# DA1470x register map
Vendor: Dialog; Series: DA1470x; File version: 1.2
CPU: CM33 r0p2, little endian, MPU, FPU, DSP, VTOR, 4 interrupt priority bits
Registers are 32-bit, read-write, reset 0x0 unless marked. A register's access mark holds for its fields unless they carry their own. Offsets are from the block's base; [hi:lo] are bit positions; 'fields as' and 'values as' point back to an identical list.

## LCDC — LCDC registers
Base 0x30030000
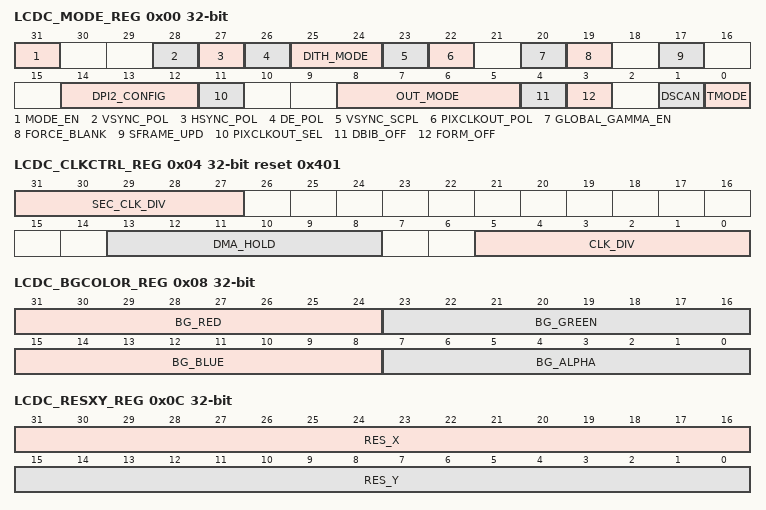
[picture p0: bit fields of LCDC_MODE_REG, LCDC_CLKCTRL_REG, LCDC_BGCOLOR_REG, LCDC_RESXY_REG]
0x00 LCDC_MODE_REG (reset mask 0x7FFFFFFF) — Display Mode
  [31] MODE_EN — Mode register. 0 : disable 1 : enable
  [28] VSYNC_POL — VSYNC polarity. 0: positive 1: negative
  [27] HSYNC_POL — HSYNC polarity. 0: positive 1: negative
  [26] DE_POL — DE polarity. 0: positive 1: negative
  [25:24] DITH_MODE — 0x00: Dithering is disabled 0x01: Dithering 18-bits mode 0x02: Dithering 16-bits mode 0x03: Dithering 15-bits mode
  [23] VSYNC_SCPL — Set VSYNC for a single cycle per line. 0: disable 1: enable
  [22] PIXCLKOUT_POL — Pixel clock out polarity. 0: positive 1: negative
  [20] GLOBAL_GAMMA_EN — When set to 1, global gamma correction is enabled
  [19] FORCE_BLANK — Forces output to blank. 0: disable 1: enable
  [17] SFRAME_UPD — Single frame update. 0: disable 1: enable
  [14:12] DPI2_CONFIG — Defines MIPI DPI-2 Configuration 0x00: RGB888 24-bits 0x01: RGB666 18-bits Configuration 1 0x02: RGB666 18-bits Configuration 2 0x03: RGB565 16-bits Configuration 1 0x04: RGB565 16-bits Configuration 2 0x05: RGB565 16-bits Configuration 3 0x06: Reserved 0x07: Reserved
  [11] PIXCLKOUT_SEL — Selects the pixel out clock for the display. 0: based on the pixel pipeline clock 1: based on the format pipeline clock See also the LCDC_CLKCTRL_REG.
  [8:5] OUT_MODE — Selection of the output mode 0000: Parallel RGB 1000: JDI MIP All the other values are reserved.
  [4] DBIB_OFF — When set to 0, DBI Type-B interface is enabled
  [3] FORM_OFF — Formating off 0: disabled 1: enabled
  [1] DSCAN — Double horizontal scan 0: disabled 1: enabled
  [0] TMODE — Test mode 0: disabled 1: enabled
0x04 LCDC_CLKCTRL_REG reset 0x401 (reset mask 0x7FFFFFFF) — Clock Divider
  [31:27] SEC_CLK_DIV — Secondary clock divider that generates the format pipeline clock. Source clock of this divider is the main clock of LCD controller. The period of the generated clock is defined as : (LCDC_SEC_CLK_DIV + 1) x period_of_main_clock.
  [13:8] DMA_HOLD — Hold time before DMA activated.
  [5:0] CLK_DIV — Clock divider that generates the pixel pipeline clock. Source clock of this divider is the format pipeline clock (see also LCDC_SEC_CLK_DIV). The period of the generated clock is defines as : LCDC_CLK_DIV x period_of_format_clk. A zero value gives division by one.
0x08 LCDC_BGCOLOR_REG (reset mask 0x7FFFFFFF) — Background Color
  [31:24] BG_RED — Red color used as background.
  [23:16] BG_GREEN — Green color used as background.
  [15:8] BG_BLUE — Blue color used as background.
  [7:0] BG_ALPHA — Alpha color used as background.
0x0C LCDC_RESXY_REG (reset mask 0x7FFFFFFF) — Resolution X,Y
  [31:16] RES_X — Resolution X in pixels.
  [15:0] RES_Y — Resolution Y in pixels.
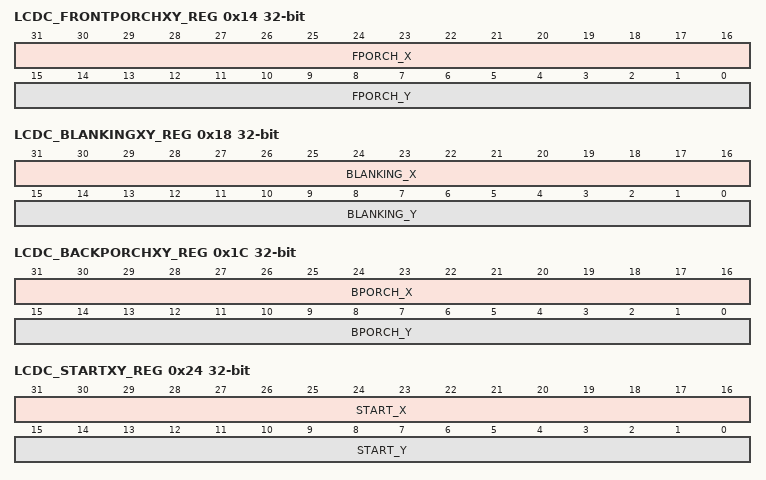
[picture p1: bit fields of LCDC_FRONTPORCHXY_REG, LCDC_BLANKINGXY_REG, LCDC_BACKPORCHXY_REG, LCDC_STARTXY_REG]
0x14 LCDC_FRONTPORCHXY_REG (reset mask 0x7FFFFFFF) — Front Porch X and Y
  [31:16] FPORCH_X — Front porch X (lines)
  [15:0] FPORCH_Y — Front porch Y (pixel clocks)
0x18 LCDC_BLANKINGXY_REG (reset mask 0x7FFFFFFF) — Blanking X and Y
  [31:16] BLANKING_X — Blanking period X (VSYNC lines)
  [15:0] BLANKING_Y — Blanking period Y (HSYNC pulse length)
0x1C LCDC_BACKPORCHXY_REG (reset mask 0x7FFFFFFF) — Back Porch X and Y
  [31:16] BPORCH_X — Back porch X (lines)
  [15:0] BPORCH_Y — Back porch Y (pixel clocks)
0x24 LCDC_STARTXY_REG (reset mask 0x7FFFFFFF) — Specifies the start position of the very first frame
  [31:16] START_X — Specify framess X dimension
  [15:0] START_Y — Specify framess Y dimension
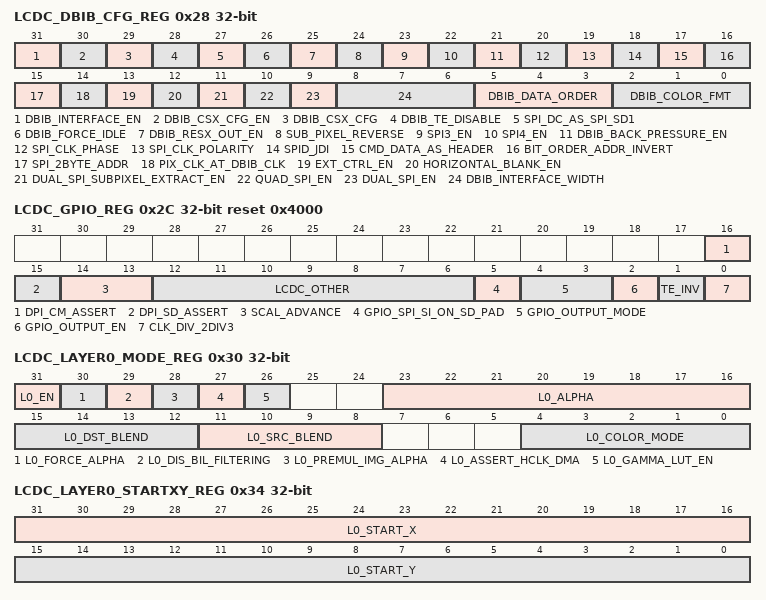
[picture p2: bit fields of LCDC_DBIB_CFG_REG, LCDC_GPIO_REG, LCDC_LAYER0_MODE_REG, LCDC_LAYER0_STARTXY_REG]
0x28 LCDC_DBIB_CFG_REG (reset mask 0x7FFFFFFF) — MIPI Config Register
  [31] DBIB_INTERFACE_EN — When set to 1, the DBI Type-B interface is activated
  [30] DBIB_CSX_CFG_EN — When set to 1, the value of the CSX signal of the DBI Type-B interface can be configured from the DBIB_CFG[29] register bit
  [29] DBIB_CSX_CFG — Sets the value of DBIB_CSX signal: CSX is set to one if DBIB_CFG[29] has the value of one CSX is set to zero if DBIB_CFG[29] has the value of zero
  [28] DBIB_TE_DISABLE — When set to 1, the DBIB_TE signal is disabled
  [27] SPI_DC_AS_SPI_SD1 — When set to 1, enables the usage of SPI_DC wire as SPI_SD1
  [26] DBIB_FORCE_IDLE — When set to 1, force DBI Type-B interface to idle state. Swap on the fly data for the interface
  [25] DBIB_RESX_OUT_EN — Drives DBIB_RESX output signal of DBI Type-B interface
  [24] SUB_PIXEL_REVERSE — Reverse sub pixel order
  [23] SPI3_EN — When set to 1, SPI 3-wire interface is enabled
  [22] SPI4_EN — When set to 1, SPI 4-wire interface is enabled
  [21] DBIB_BACK_PRESSURE_EN — When set to 1, Enables back-pressure for DBI Type-B interface
  [20] SPI_CLK_PHASE — Sets SPI Clock Phase
  [19] SPI_CLK_POLARITY — Sets SPI Clock Polarity
  [18] SPID_JDI
  [17] CMD_DATA_AS_HEADER — When set to 1, command data are used as header of each line
  [16] BIT_ORDER_ADDR_INVERT — When set to 1, inverts the bit-order of the horizontal line address (used along with DBIB_CFG[17] register bit)
  [15] SPI_2BYTE_ADDR — When set to 1, two-byte address is sent with each horizontal line (SPI)
  [14] PIX_CLK_AT_DBIB_CLK — When set to 1, expose pixel generation clock on the DBIB_CLK
  [13] EXT_CTRL_EN — When set to 1, enables the external control
  [12] HORIZONTAL_BLANK_EN — When set to 1, enables the horizontal blanking
  [11] DUAL_SPI_SUBPIXEL_EXTRACT_EN — When set to 1, Enables DualSPI sub-pixel transaction
  [10] QUAD_SPI_EN — When set to 1, Enables QuadSPI
  [9] DUAL_SPI_EN — When set to 1, Enables DualSPI
  [8:6] DBIB_INTERFACE_WIDTH — Set DBI Type-B interface width (8, 9 or 16 bits) and the serial interface: 0x0: 8-bit interface 0x1: 9-bit interface 0x2: 16-bit interface 0x3: SPI 0x4: Dual SPI 0x5: Quad SPI
  [5:3] DBIB_DATA_ORDER — Set the data order of the 8-bit data word: 0x0: option 0 0x1: option 1 0x2: option 2 0x3: option 3 0x4: option 4 0x5: Reserved 0x6: Reserved 0x7: Reserved
  [2:0] DBIB_COLOR_FMT — Defines the output format and depends of the type of the output interface. For the SPI3/SPI4 are supported the following formats: 0x0 : Reserved 0x1 : RGB111 0x2 : RGB332 0x3 : RGB444 0x4 : Reserved 0x5 : RGB565 0x6 : RGB666 0x7 : RGB888
0x2C LCDC_GPIO_REG reset 0x4000 — General Purpose IO (8-bits)
  [16] DPI_CM_ASSERT wo — Assert DPI-2 Color Mode signal
  [15] DPI_SD_ASSERT wo — Assert DPI-2 Shutdown signal
  [14:13] SCAL_ADVANCE — scalar advance
  [12:6] LCDC_OTHER
  [5] GPIO_SPI_SI_ON_SD_PAD — Enable to have the SPI SI on the SPI SD pad
  [4:3] GPIO_OUTPUT_MODE — Select the mode that should be mapped on the GPIO pins 0x0 = JDI 0x1 = DPI 0x2 = DBI 0x3 = SPI
  [2] GPIO_OUTPUT_EN — Enable the GPIO pins for LCDC control. The GPIO_OUTPUT_MODE is used to define what LCDC pins will be mapped towards the GPIO pins.
  [1] TE_INV — Applies an inversion on the TE (tearing effect) signal. 0 : the inversion is not applied on the TE signal 1 : the inversion is applied on TE signal
  [0] CLK_DIV_2DIV3 — Divide clock by 2/3 clock-gating. This is required when the DSI-DPHY is used with 2 lanes active.
0x30 LCDC_LAYER0_MODE_REG (reset mask 0x7FFFFFFF) — Layer0 Mode
  [31] L0_EN — Enable layer. 0 : disable 1 : enable
  [30] L0_FORCE_ALPHA — When set to 1, force alpha with global alpha
  [29] L0_DIS_BIL_FILTERING — When set to 0, bilinear filtering is enabled. Scaler should be enabled
  [28] L0_PREMUL_IMG_ALPHA — When set to 1, premultiply image alpha is enabled
  [27] L0_ASSERT_HCLK_DMA — When set to 1, HLOCK signal on AHB DMAs is asserted
  [26] L0_GAMMA_LUT_EN — When set to 1, Gamma Look Up Table is enabled
  [23:16] L0_ALPHA — Alpha layer global value (0x00-0xFF range)
  [15:12] L0_DST_BLEND — Destinary Blending Function 0000: BLEND ZERO 0001: BLEND ONE 0010: BLEND ALPHA SRC 0011: BLEND ALPHA GBL 0100: BLEND ALPHA SRCGBL 0101: BLEND INV SRC 0110: BLEND INV GBL 0111: BLEND INV SRCGBL 1010: BLEND ALPHA DST 1101: BLEND INV DST
  [11:8] L0_SRC_BLEND — Source Blending Function 0000: BLEND ZERO 0001: BLEND ONE 0010: BLEND ALPHA SRC 0011: BLEND ALPHA GBL 0100: BLEND ALPHA SRCGBL 0101: BLEND INV SRC 0110: BLEND INV GBL 0111: BLEND INV SRCGBL 1010: BLEND ALPHA DST 1101: BLEND INV DST
  [4:0] L0_COLOR_MODE — Color Mode: 00001: 16-bit RGBX5551 color format, 00010: 32-bit RGBX8888 color format, 00100: 8-bit RGB332 color format, 00101: 16-bit RGB565 color format, 00110: 32-bit XRGB8888, 00111: L8 Grayscale/Palette format, 01000: L1 Grayscale/Palette format, 01001: L4 Grayscale/Palette format, 01101: ABGR8888, 01110: BGRA8888
0x34 LCDC_LAYER0_STARTXY_REG (reset mask 0x7FFFFFFF) — Layer0 Start XY
  [31:16] L0_START_X — Start X (offset pixels)
  [15:0] L0_START_Y — Start Y (offset pixels)
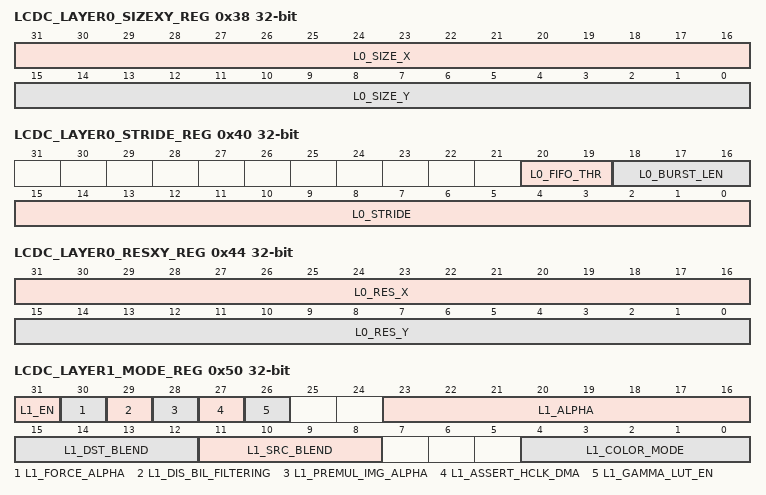
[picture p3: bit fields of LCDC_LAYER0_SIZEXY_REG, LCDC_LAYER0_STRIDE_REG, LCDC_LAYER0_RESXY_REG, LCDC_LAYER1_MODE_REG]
0x38 LCDC_LAYER0_SIZEXY_REG (reset mask 0x7FFFFFFF) — Layer0 Size XY
  [31:16] L0_SIZE_X — Size X (Size of layer in pixels)
  [15:0] L0_SIZE_Y — Size Y (Size of layer in pixels)
0x3C LCDC_LAYER0_BASEADDR_REG (reset mask 0x7FFFFFFF) — Layer0 Base Addr
  [31:0] L0_BASE_ADDR — Base Address of the frame buffer
0x40 LCDC_LAYER0_STRIDE_REG — Layer0 Stride
  [20:19] L0_FIFO_THR — Layer dma fifo threshold burst start 00: half fifo (default) 01: 2 burst size 10: 4 burst size 11: 8 burst size
  [18:16] L0_BURST_LEN — Layer burst length 000: 16-beats (default) 001: 2-beats 010: 4-beats 011: 8-beats 100: 16-beats
  [15:0] L0_STRIDE — Layer Stride (distance from line to line in bytes)
0x44 LCDC_LAYER0_RESXY_REG (reset mask 0x7FFFFFFF) — Layer0 Res XY
  [31:16] L0_RES_X — Resolution X (Resolution of layer in pixels)
  [15:0] L0_RES_Y — Resolution Y (Resolution of layer in pixels)
0x50 LCDC_LAYER1_MODE_REG (reset mask 0x7FFFFFFF) — Layer1 Mode
  [31] L1_EN — Enable layer. 0 : disable 1 : enable
  [30] L1_FORCE_ALPHA — When set to 1, force alpha with global alpha
  [29] L1_DIS_BIL_FILTERING — When set to 0, bilinear filtering is enabled. Scaler should be enabled
  [28] L1_PREMUL_IMG_ALPHA — When set to 1, premultiply image alpha is enabled
  [27] L1_ASSERT_HCLK_DMA — When set to 1, HLOCK signal on AHB DMAs is asserted
  [26] L1_GAMMA_LUT_EN — When set to 1, Gamma Look Up Table is enabled
  [23:16] L1_ALPHA — Alpha layer global value (0x00-0xFF range)
  [15:12] L1_DST_BLEND — Destinary Blending Function 0000: BLEND ZERO 0001: BLEND ONE 0010: BLEND ALPHA SRC 0011: BLEND ALPHA GBL 0100: BLEND ALPHA SRCGBL 0101: BLEND INV SRC 0110: BLEND INV GBL 0111: BLEND INV SRCGBL 1010: BLEND ALPHA DST 1101: BLEND INV DST
  [11:8] L1_SRC_BLEND — Source Blending Function 0000: BLEND ZERO 0001: BLEND ONE 0010: BLEND ALPHA SRC 0011: BLEND ALPHA GBL 0100: BLEND ALPHA SRCGBL 0101: BLEND INV SRC 0110: BLEND INV GBL 0111: BLEND INV SRCGBL 1010: BLEND ALPHA DST 1101: BLEND INV DST
  [4:0] L1_COLOR_MODE — Color Mode: 00001: 16-bit RGBX5551 color format, 00010: 32-bit RGBX8888 color format, 00100: 8-bit RGB332 color format, 00101: 16-bit RGB565 color format, 00110: 32-bit XRGB8888, 00111: L8 Grayscale/Palette format, 01000: L1 Grayscale/Palette format, 01001: L4 Grayscale/Palette format, 01101: ABGR8888, 01110: BGRA8888
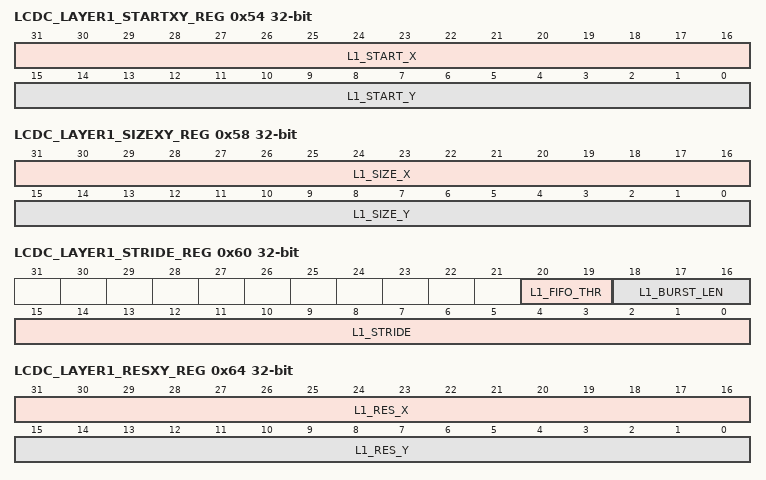
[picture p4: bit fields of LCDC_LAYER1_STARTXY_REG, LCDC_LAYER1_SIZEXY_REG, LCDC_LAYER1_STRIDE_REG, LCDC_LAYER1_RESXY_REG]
0x54 LCDC_LAYER1_STARTXY_REG (reset mask 0x7FFFFFFF) — Layer0 Start XY
  [31:16] L1_START_X — Start X (offset pixels)
  [15:0] L1_START_Y — Start Y (offset pixels)
0x58 LCDC_LAYER1_SIZEXY_REG (reset mask 0x7FFFFFFF) — Layer1 Size XY
  [31:16] L1_SIZE_X — Size X (Size of layer in pixels)
  [15:0] L1_SIZE_Y — Size Y (Size of layer in pixels)
0x5C LCDC_LAYER1_BASEADDR_REG (reset mask 0x7FFFFFFF) — Layer1 Base Addr
  [31:0] L1_BASE_ADDR — Base Address of the frame buffer
0x60 LCDC_LAYER1_STRIDE_REG — Layer1 Stride
  [20:19] L1_FIFO_THR — Layer dma fifo threshold burst start 00: half fifo (default) 01: 2 burst size 10: 4 burst size 11: 8 burst size
  [18:16] L1_BURST_LEN — Layer burst length 000: 16-beats (default) 001: 2-beats 010: 4-beats 011: 8-beats 100: 16-beats
  [15:0] L1_STRIDE — Layer Stride (distance from line to line in bytes)
0x64 LCDC_LAYER1_RESXY_REG (reset mask 0x7FFFFFFF) — Layer1 Res XY
  [31:16] L1_RES_X — Resolution X (Resolution of layer in pixels)
  [15:0] L1_RES_Y — Resolution Y (Resolution of layer in pixels)
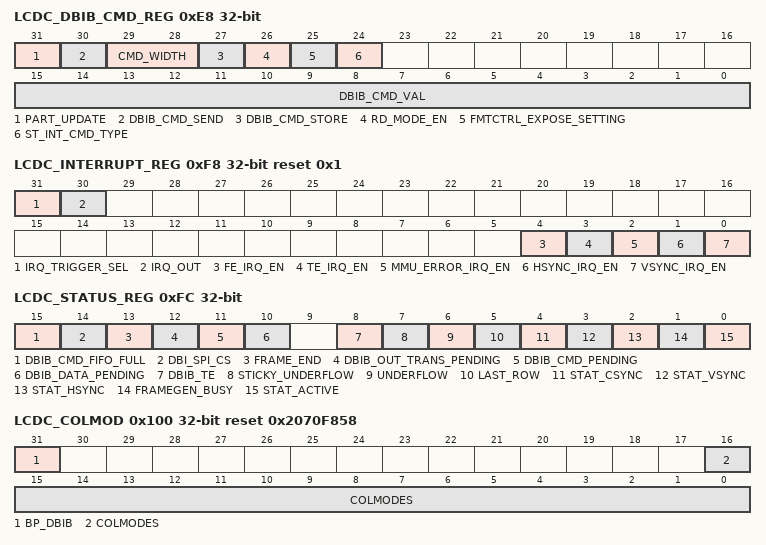
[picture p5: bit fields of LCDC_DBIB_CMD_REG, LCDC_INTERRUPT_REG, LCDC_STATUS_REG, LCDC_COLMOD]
0xE8 LCDC_DBIB_CMD_REG (reset mask 0x7FFFFFFF) — MIPI DBIB Command Register
  [31] PART_UPDATE — When set to 0, indicates that the command data are the Base address for partial update. Applied on SPI/JDI-SPI type
  [30] DBIB_CMD_SEND — Send command to the DBI interface
  [29:28] CMD_WIDTH — Determine the command width. Applicable only on the QuadSPI 0x00: 1 Byte 0x01: 2 Bytes 0x02: 3 Bytes 0x03: Reserved
  [27] DBIB_CMD_STORE — This bit has meaning only when LCDC_DBIB_CFG_REG[LCDC_DBIB_SPI_JDI] = 1. When is enabled, stores the LCDC_DBIB_CMD_VAL to the register that keeps the Y position.
  [26] RD_MODE_EN — When sets to 1, read mode is enabled
  [25] FMTCTRL_EXPOSE_SETTING — When sets to 1, FMTCTRL[15:8] is exposed on DBIB_CT pins and FMTCTRL[31] on DBIB_GE else FMTCTRL[15:8] is exposed on DBIB_CT pins and FMTCTRL[30] on DBIB_GE
  [24] ST_INT_CMD_TYPE — When sets to 1, store internally a command type which is transmitted at the beggining of each scanline
  [15:0] DBIB_CMD_VAL — Data to send to the DBI interface
0xEC LCDC_DBIB_RDAT (reset mask 0x7FFFFFFF) — Data read by DBI Type-B/SPI interface
  [31:0] DBIB_RDAT — On Write: 31-30 bits: Specify the number of read cycles 0x0: 8 cycles 0x1: 16 cycles 0x2: 24 cycles 0x3: Used along with FMTCTRL[20:16] register bits 29-0 bits: Reserved On Read: 31-0 bits: Read data from DBI Type-B/SPI interfaces
0xF0 LCDC_CONF_REG reset 0x3359 — Supported config
  [15:0] CONF ro
0xF4 LCDC_IDREG_REG reset 0x7FFFFFFF (reset mask 0x7FFFFFFF) — Identification Register
  [31:0] NEMADC_ID ro — Identification register
0xF8 LCDC_INTERRUPT_REG reset 0x1 (reset mask 0x7FFFFFFF) — Interrupt Register
  [31] IRQ_TRIGGER_SEL — IRQ trigger control 0: Level triggering 1: Edge triggering In the case of the level triggering, the request remains active in the LCDC until to be cleared. The request can be cleared by performing a write access in the LCDC_INTERRUPT_REG. This is not required in the case of the edge triggering.
  [30] IRQ_OUT
  [4] FE_IRQ_EN
  [3] TE_IRQ_EN
  [2] MMU_ERROR_IRQ_EN
  [1] HSYNC_IRQ_EN — HSYNC interrupt enabled
  [0] VSYNC_IRQ_EN — VSYNC or TE interrupt enabled. See also the configuration bit LCDC_DBIB_CFG_REG[LCDC_DBIB_TE_DIS] for the TE signal.
0xFC LCDC_STATUS_REG — Status Register
  [15] DBIB_CMD_FIFO_FULL ro — Indicates if the command FIFO is full
  [14] DBI_SPI_CS ro — Indicates DBI/SPI CS status
  [13] FRAME_END ro — Frame end (active high)
  [12] DBIB_OUT_TRANS_PENDING ro — Pending output transaction in DBI Type-B interface
  [11] DBIB_CMD_PENDING ro — Transferring of command in progress. 0: idle 1: in progress
  [10] DBIB_DATA_PENDING ro — Pending RGB data in DBI Type-B interface
  [8] DBIB_TE ro — The DBIB tearing effect signal
  [7] STICKY_UNDERFLOW ro — Sticky underflow(clear with write in the LCDC_INTERRUPT_REG) 0: There is no underflow 1: Underflow has been detected.Remains high until to be cleared by performing a write access on the register LCDC_INTERRUPT_REG.
  [6] UNDERFLOW ro — Underflow on the current transfer. 0: There is no underflow 1: Underflow has been detected.
  [5] LAST_ROW ro — Last row (Last row is currently displayed)
  [4] STAT_CSYNC ro — CSYNC signal level
  [3] STAT_VSYNC ro — VSYNC signal level
  [2] STAT_HSYNC ro — HSYNC signal level
  [1] FRAMEGEN_BUSY ro — The frame generator is busy (active high).
  [0] STAT_ACTIVE ro — Active (When not in vertical blanking)
0x100 LCDC_COLMOD reset 0x2070F858 (reset mask 0x7FFFFFFF) — Color mode status register
  [31] BP_DBIB ro — Indicates that back pressure support for the DBI Type B interface is enabled
  [16:0] COLMODES ro — 16 bit: Indicates that the LUT8 color format is enabled 15 bit: Indicates that the RGBA5551 16-bit color format is enabled 14 bit: Indicates that the RGBA8888 32-bit color format is enabled 13 bit: Indicates that the RGB332 8-bit color format is enabled 12 bit: Indicates that the RGB565 16-bit color format is enabled 11 bit: Indicates that the ARGB8888 32-bit color format is enabled 10 bit: Indicates that the L8 color format is enabled 9 bit: Indicates that the L1 color format is enabled 8 bit: Indicates that the L4 color format is enabled 7 bit: Indicates that the YUYV color format is enabled 6 bit: Indicates that the RGB888 24-bit color format is enabled 5 bit: Indicates that the YUY2 color format is enabled 4 bit: Indicates that the ABGR8888 32-bit color format is enabled 3 bit: Indicates that the BGRA8888 32-bit color format is enabled 2 bit: Indicates that the V_YUV420 color format is enabled 1 bit: Indicates that the TLYUV420 color format is enabled 0 bit: Indicates that the TSc4/TSc6 propietary color format is enabled
0x184 LCDC_CRC_REG (reset mask 0x7FFFFFFF) — CRC check
  [31:0] CRC ro — CRC check.
0x1A0 LCDC_FMTCTRL_REG (reset mask 0x7FFFFFFF) — DBI and JDI format control
  [31:0] FMTCTRL — When DBI-Type B Interface is selected: Bits Description 31 bit : Candidate for DBIB_GE, associated with [15:8] bits (DSI interface specific) 30 bit : Candidate for DBIB_GE, associated with [7:0] bits (DSI interface specific) 29-21 bits: Reserved 20-16 bits: Specify the number of read cycles for SPI/DBI Type-B. Used along with DBIB_CFG[31:30] register bits 0x0: 1 cycles 0x1: 2 cycles 0x2: 3 cycles . . 0x30: 31 cycles 0x31: 32 cycles 15-8 bits : Candidate DBIB_CT (DSI interface specific) 7-0 bits : Candidate DBIB_CT (DSI interface specific) When JDI-Parallel Interface is selected: Bits Description 31 bit : Mute DPI outputs 30 bit : Mask DPIREADY input 29 bit : Reserved 28-26 bits : JDI HST width 25-23 bits : JDI HST offset 22-13 bits : JDI VST width 12-3 bits : JDI VST offset 2-0 bits : Reserved
0x1A4 LCDC_FMTCTRL_2_REG (reset mask 0x7FFFFFFF) — DBI and JDI format control
  [31:0] FMTCTRL — Bits Description When DBI-Type B Interface is selected: Bits Description 31-16 bits: Reserved 15-0 bits: Specify the blanking period length for the X dimension When JDI-Parallel Interface is selected: Bits Description 31-20 bits: Reserved 19-10 bits: JDI ENB width 9-0 bits: JDI ENB offset
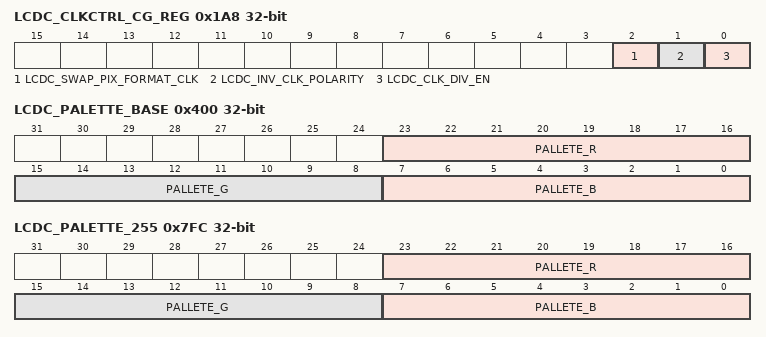
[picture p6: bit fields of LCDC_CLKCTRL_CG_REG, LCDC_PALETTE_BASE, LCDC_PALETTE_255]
0x1A8 LCDC_CLKCTRL_CG_REG — Controls the CLock Gaters and the routing of format and pixel clock
  [2] LCDC_SWAP_PIX_FORMAT_CLK, [1] LCDC_INV_CLK_POLARITY, [0] LCDC_CLK_DIV_EN
0x400 LCDC_PALETTE_BASE — Global palette/gamma correction
  [23:16] PALLETE_R wo — Gamma ramp red bits
  [15:8] PALLETE_G wo — Gamma ramp green bits
  [7:0] PALLETE_B wo — Gamma ramp blue bits
0x7FC LCDC_PALETTE_255 — Global palette/gamma correction
  fields as LCDC_PALETTE_BASE
